VERSION ""

NS_ :

BS_:

BU_:

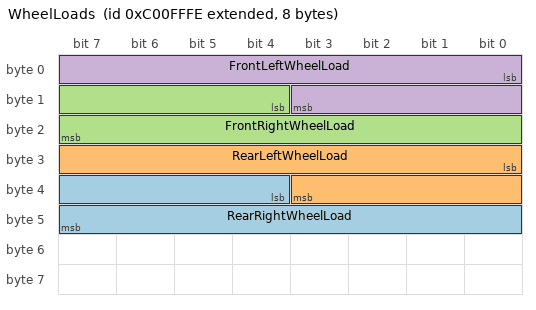
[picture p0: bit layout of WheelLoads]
BO_ 2348875774 WheelLoads: 8 Vector__XXX
 SG_ RearRightWheelLoad : 36|12@1+ (1,0) [0|4095] "" Vector__XXX
 SG_ RearLeftWheelLoad : 24|12@1+ (1,0) [0|4095] "" Vector__XXX
 SG_ FrontRightWheelLoad : 12|12@1+ (1,0) [0|4095] "" Vector__XXX
 SG_ FrontLeftWheelLoad : 0|12@1+ (1,0) [0|4095] "" Vector__XXX

BO_ 2281766910 SensorsStatus: 8 Vector__XXX
 SG_ SensorFault : 1|1@1+ (1,0) [0|1] "" Vector__XXX
 SG_ AngleFault : 0|1@1+ (1,0) [0|1] "" Vector__XXX

BO_ 2214658046 BodyAngles: 8 Vector__XXX
 SG_ AngleY : 8|8@1+ (1,-128) [-128|127] "deg" Vector__XXX
 SG_ AngleX : 0|8@1+ (1,-128) [-128|127] "deg" Vector__XXX

BO_ 2147549182 AxleLoads: 8 Vector__XXX
 SG_ AxleLoad : 0|16@1+ (0.1,0) [0|6553.5] "kg" Vector__XXX

CM_ BO_ 2348875774 "Wheel Load prototype message for Payload Management";
CM_ BO_ 2281766910 "Sensor Status prototype message for Payload Management";
CM_ BO_ 2214658046 "Body Angle prototype message  for Payload Management";
CM_ BO_ 2147549182 "Axle Load prototype message  for Payload Management";
CM_ SG_ 2147549182 AxleLoad "HeightMeasured = L*sin(RotationAngle), where L - sensor lever, default 50 mm accordance to Swoboda Ride Height Sensor specification";
BA_DEF_ BO_  "Producer" STRING ;
BA_DEF_ SG_  "SigType" ENUM  "Default","Range","RangeSigned","ASCII","Discrete","Control","ReferencePGN","DTC","StringDelimiter","StringLength","StringLengthControl","MessageCounter","MessageChecksum";
BA_DEF_ SG_  "GenSigEVName" STRING ;
BA_DEF_ SG_  "GenSigILSupport" ENUM  "No","Yes";
BA_DEF_ SG_  "GenSigSendType" ENUM  "Cyclic","OnWrite","OnWriteWithRepetition","OnChange","OnChangeWithRepetition","IfActive","IfActiveWithRepetition","NoSigSendType";
BA_DEF_ SG_  "GenSigStartValue" INT 0 2147483647;
BA_DEF_ BO_  "GenMsgILSupport" ENUM  "No","Yes";
BA_DEF_ BU_  "NmStationAddress" INT 0 255;
BA_DEF_ BO_  "GenMsgSendType" ENUM  "cyclic","NotUsed","IfActive","NotUsed","NotUsed","NotUsed","NotUsed","NotUsed","noMsgSendType";
BA_DEF_ BO_  "GenMsgRequestable" INT 0 1;
BA_DEF_ BO_  "GenMsgCycleTime" INT 0 3600000;
BA_DEF_  "DBName" STRING ;
BA_DEF_  "BusType" STRING ;
BA_DEF_  "ProtocolType" STRING ;
BA_DEF_ BO_  "VFrameFormat" ENUM  "StandardCAN","ExtendedCAN","reserved","J1939PG";
BA_DEF_DEF_ "Producer" "SCS";
BA_DEF_DEF_  "SigType" "Default";
BA_DEF_DEF_  "GenSigEVName" "Env@Nodename_@Signame";
BA_DEF_DEF_  "GenSigILSupport" "Yes";
BA_DEF_DEF_  "GenSigSendType" "NoSigSendType";
BA_DEF_DEF_  "GenSigStartValue" 0;
BA_DEF_DEF_  "GenMsgILSupport" "Yes";
BA_DEF_DEF_  "NmStationAddress" 254;
BA_DEF_DEF_  "GenMsgSendType" "noMsgSendType";
BA_DEF_DEF_  "GenMsgRequestable" 1;
BA_DEF_DEF_  "GenMsgCycleTime" 0;
BA_DEF_DEF_  "DBName" "";
BA_DEF_DEF_  "BusType" "CAN";
BA_DEF_DEF_  "ProtocolType" "J1939";
BA_DEF_DEF_  "VFrameFormat" "J1939PG";
BA_ "DBName" "Payload";
BA_ "GenMsgCycleTime" BO_ 2348875774 100;
BA_ "GenMsgSendType" BO_ 2348875774 0;
BA_ "GenMsgCycleTime" BO_ 2281766910 100;
BA_ "GenMsgSendType" BO_ 2281766910 0;
BA_ "GenMsgCycleTime" BO_ 2214658046 100;
BA_ "GenMsgSendType" BO_ 2214658046 0;
BA_ "GenMsgCycleTime" BO_ 2147549182 100;
BA_ "GenMsgSendType" BO_ 2147549182 0;
BA_ "GenSigStartValue" SG_ 2214658046 AngleY 128;
BA_ "GenSigStartValue" SG_ 2214658046 AngleX 128;
